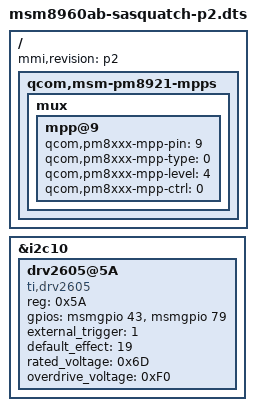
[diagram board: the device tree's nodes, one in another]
/dts-v1/;

/include/ "msm8960ab-sasquatch-common.dtsi"

/include/ "msm8960ab-sasquatch-p2-legacy.dtsi"

/ {
	mmi,revision = "p2";

	/* PM8921 - MPP */
	qcom,msm-pm8921-mpps {
		mux {
			mpp@9 {
				/* EMU_DMB_PPD_DET_N */
				qcom,pm8xxx-mpp-pin = <9>;

				/*
				 * type   : D_INPUT
				 * level  : L17
				 * ctrl   : DIN_TO_INT
				 */
				qcom,pm8xxx-mpp-type = <0>;
				qcom,pm8xxx-mpp-level = <4>;
				qcom,pm8xxx-mpp-ctrl = <0>;
			};
		};
	};
};

/* GSBI10 - I2C */
&i2c10 {
	/* TI drv2605 */
	drv2605@5A {
		compatible = "ti,drv2605";
		reg = <0x5A>;
		gpios = <&msmgpio 43 0>,    /* EN_GPIO */
			<&msmgpio 79 0>;    /* Trigger */

		external_trigger = <1>;
		default_effect = <19>;      /* Strong Click 3 60% */
		rated_voltage = <0x6D>;
		overdrive_voltage = <0xF0>;
	};
};
